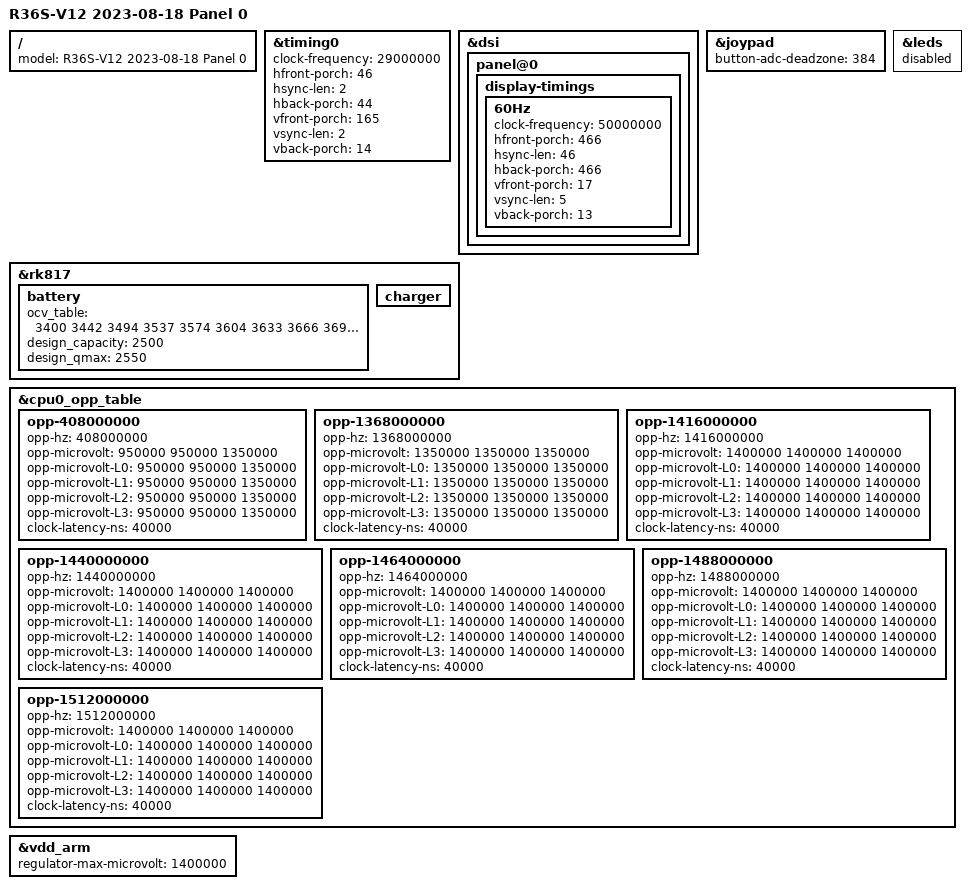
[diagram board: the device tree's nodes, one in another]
// SPDX-License-Identifier: (GPL-2.0+ OR MIT)
/* Only for R36S-V12 2023-08-18 Panel 0. Not yet boot-tested.
 * Includes the pinned GPL-2.0+/MIT Hardkernel-derived R35S description.
 * Panel/input/battery values were compared with the installed DTB.
 * Keep the base GPU OPPs; the CPU OPPs up to the stock 1512 MHz (M7, opt-in).
 * M3e: the BSP's 408 MHz CPU OPP is restored (see &cpu0_opp_table).
 */
#include "rk3326-r35s-linux.dts"

/ {
    model = "R36S-V12 2023-08-18 Panel 0";
};

&timing0 {
    clock-frequency = <29000000>;
    hfront-porch = <46>;
    hsync-len = <2>;
    hback-porch = <44>;
    vfront-porch = <165>;
    vsync-len = <2>;
    vback-porch = <14>;
};

&dsi {
    panel@0 {
        display-timings {
            /delete-node/ 50Hz;
            /delete-node/ 75Hz;
            /* M3d: the rk351 r35s timing (29 MHz, v 165/2/14) let the bottom
             * rows show the top rows, intermittently and persisting once
             * started (seen 2026-11-12). The ST7703 init (b3 SETRGBIF) expects short
             * vertical porches: use the stock dArkOSen Panel 0 vertical
             * timing and pixel clock (50 MHz, v 17/5/13, as ROCKNIX), with
             * horizontal porches widened from 450 to 466 so that
             * 50 MHz / (1618 x 515) = 60.0046 Hz instead of stock 61.2 Hz
             * (device/config/screen/refresh says 60.004560 to match). */
            60Hz {
                clock-frequency = <50000000>;
                hfront-porch = <466>;
                hsync-len = <46>;
                hback-porch = <466>;
                vfront-porch = <17>;
                vsync-len = <5>;
                vback-porch = <13>;
            };
        };
    };
};

&joypad {
    button-adc-deadzone = <384>;
};

&rk817 {
    battery {
        /* OCV table: the reference DTB's. Capacity: measured on the R35S
         * (2026-11-14, 94% -> 3% idle run): ~2530 mAh, not the reference
         * 3140/3454. The BSP never learns FCC; it clamps the stored one
         * (3380 from older firmware) to design_qmax at every boot. */
        ocv_table = <3400 3442 3494 3537 3574 3604 3633
                     3666 3697 3726 3760 3790 3812 3842
                     3886 3928 3955 3990 4036 4105 4177>;
        design_capacity = <2500>;
        design_qmax = <2550>;
    };
    charger {
        /delete-property/ bat_low_gpio;
    };
};

&leds {
    status = "disabled";
};

&cpu0_opp_table {
    /* M3e: rk3326-r35s-linux.dts deletes 408/600/816 MHz, so the CPU never
     * went below 1008 MHz / 1.175 V. Restore px30.dtsi's 408 MHz OPP
     * (0.95 V on every leakage bin; ROCKNIX keeps it too) for idle. Without
     * opp-suspend: suspend keeps its current behaviour. */
    opp-408000000 {
        opp-hz = /bits/ 64 <408000000>;
        opp-microvolt = <950000 950000 1350000>;
        opp-microvolt-L0 = <950000 950000 1350000>;
        opp-microvolt-L1 = <950000 950000 1350000>;
        opp-microvolt-L2 = <950000 950000 1350000>;
        opp-microvolt-L3 = <950000 950000 1350000>;
        clock-latency-ns = <40000>;
    };

    /* M7: the stock dArkOSen Panel 0 OPPs above 1296 MHz (same values as
     * its DTB; rockchip,max-volt stays 1.35 V, so the 1.40 V entries run
     * clamped at 1.35 V exactly as on stock). The CPU stays capped at
     * 1296 MHz unless the user raises Danger -> CPU speed (decision 13:
     * opt-in, off by default; muos-governor applies danger/cpu_max). */
    opp-1368000000 {
        opp-hz = /bits/ 64 <1368000000>;
        opp-microvolt = <1350000 1350000 1350000>;
        opp-microvolt-L0 = <1350000 1350000 1350000>;
        opp-microvolt-L1 = <1350000 1350000 1350000>;
        opp-microvolt-L2 = <1350000 1350000 1350000>;
        opp-microvolt-L3 = <1350000 1350000 1350000>;
        clock-latency-ns = <40000>;
    };
    opp-1416000000 {
        opp-hz = /bits/ 64 <1416000000>;
        opp-microvolt = <1400000 1400000 1400000>;
        opp-microvolt-L0 = <1400000 1400000 1400000>;
        opp-microvolt-L1 = <1400000 1400000 1400000>;
        opp-microvolt-L2 = <1400000 1400000 1400000>;
        opp-microvolt-L3 = <1400000 1400000 1400000>;
        clock-latency-ns = <40000>;
    };
    opp-1440000000 {
        opp-hz = /bits/ 64 <1440000000>;
        opp-microvolt = <1400000 1400000 1400000>;
        opp-microvolt-L0 = <1400000 1400000 1400000>;
        opp-microvolt-L1 = <1400000 1400000 1400000>;
        opp-microvolt-L2 = <1400000 1400000 1400000>;
        opp-microvolt-L3 = <1400000 1400000 1400000>;
        clock-latency-ns = <40000>;
    };
    opp-1464000000 {
        opp-hz = /bits/ 64 <1464000000>;
        opp-microvolt = <1400000 1400000 1400000>;
        opp-microvolt-L0 = <1400000 1400000 1400000>;
        opp-microvolt-L1 = <1400000 1400000 1400000>;
        opp-microvolt-L2 = <1400000 1400000 1400000>;
        opp-microvolt-L3 = <1400000 1400000 1400000>;
        clock-latency-ns = <40000>;
    };
    opp-1488000000 {
        opp-hz = /bits/ 64 <1488000000>;
        opp-microvolt = <1400000 1400000 1400000>;
        opp-microvolt-L0 = <1400000 1400000 1400000>;
        opp-microvolt-L1 = <1400000 1400000 1400000>;
        opp-microvolt-L2 = <1400000 1400000 1400000>;
        opp-microvolt-L3 = <1400000 1400000 1400000>;
        clock-latency-ns = <40000>;
    };
    opp-1512000000 {
        opp-hz = /bits/ 64 <1512000000>;
        opp-microvolt = <1400000 1400000 1400000>;
        opp-microvolt-L0 = <1400000 1400000 1400000>;
        opp-microvolt-L1 = <1400000 1400000 1400000>;
        opp-microvolt-L2 = <1400000 1400000 1400000>;
        opp-microvolt-L3 = <1400000 1400000 1400000>;
        clock-latency-ns = <40000>;
    };
};

&vdd_arm {
    /* M7: as stock (needed by the 1.40 V OPP entries above). */
    regulator-max-microvolt = <1400000>;
};
